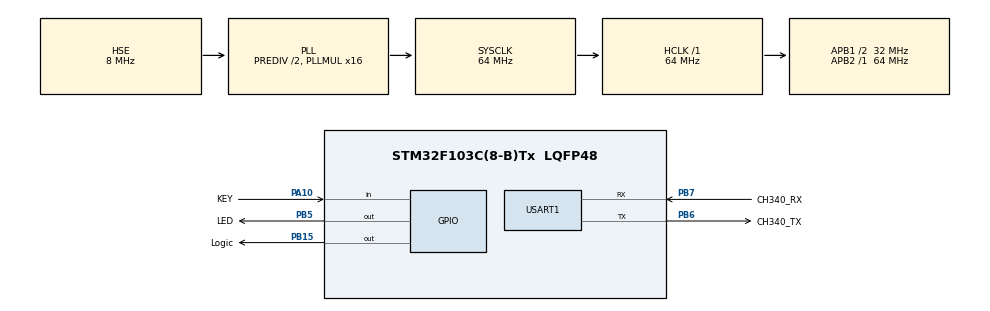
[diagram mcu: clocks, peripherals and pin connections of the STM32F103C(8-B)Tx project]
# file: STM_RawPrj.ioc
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Mcu.Family=STM32F1
Mcu.Name=STM32F103C(8-B)Tx
Mcu.Package=LQFP48
NVIC.PriorityGroup=NVIC_PRIORITYGROUP_4
PA10.GPIO_Label=KEY
PA10.Signal=GPIO_Input
PA13.GPIO_Label=SYS_SWDIO
PA13.Mode=Trace_Asynchronous_SW
PA13.Signal=SYS_JTMS-SWDIO
PA14.GPIO_Label=SYS_SWCLK
PA14.Mode=Trace_Asynchronous_SW
PA14.Signal=SYS_JTCK-SWCLK
PB15.GPIO_Label=Logic
PB15.GPIO_Speed=GPIO_SPEED_FREQ_HIGH
PB15.Signal=GPIO_Output
PB3.GPIO_Label=SYS_SWO
PB3.Mode=Trace_Asynchronous_SW
PB3.Signal=SYS_JTDO-TRACESWO
PB5.GPIO_Label=LED
PB5.GPIO_PuPd=GPIO_NOPULL
PB5.GPIO_Speed=GPIO_SPEED_FREQ_LOW
PB5.Signal=GPIO_Output
PB6.GPIO_Label=CH340_TX
PB6.Mode=Asynchronous
PB6.Signal=USART1_TX
PB7.GPIO_Label=CH340_RX
PB7.Mode=Asynchronous
PB7.Signal=USART1_RX
PC14-OSC32_IN.Mode=LSE-External-Oscillator
PC14-OSC32_IN.Signal=RCC_OSC32_IN
PC15-OSC32_OUT.Mode=LSE-External-Oscillator
PC15-OSC32_OUT.Signal=RCC_OSC32_OUT
PD0-OSC_IN.Mode=HSE-External-Oscillator
PD0-OSC_IN.Signal=RCC_OSC_IN
PD1-OSC_OUT.Mode=HSE-External-Oscillator
PD1-OSC_OUT.Signal=RCC_OSC_OUT
ProjectManager.HeapSize=0x200
ProjectManager.StackSize=0x400
ProjectManager.TargetToolchain=MDK-ARM V5.32
RCC.AHBFreq_Value=64000000
RCC.APB1CLKDivider=RCC_HCLK_DIV2
RCC.APB1Freq_Value=32000000
RCC.APB1TimFreq_Value=64000000
RCC.APB2Freq_Value=64000000
RCC.APB2TimFreq_Value=64000000
RCC.EnbaleCSS=true
RCC.HCLKFreq_Value=64000000
RCC.HSEDivPLL=RCC_HSE_PREDIV_DIV2
RCC.HSICalibrationValue=16
RCC.PLLMUL=RCC_PLL_MUL16
RCC.PLLSourceVirtual=RCC_PLLSOURCE_HSE
RCC.RCC_MCOSource=RCC_MCO1SOURCE_HSE
RCC.SYSCLKFreq_VALUE=64000000
RCC.SYSCLKSource=RCC_SYSCLKSOURCE_PLLCLK
RCC.USBFreq_Value=64000000
USART1.VirtualMode=VM_ASYNC
board=custom

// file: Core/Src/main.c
/* USER CODE BEGIN Header */
/**
  ******************************************************************************
  * @file           : main.c
  * @brief          : Main program body
  ******************************************************************************
  * @attention
  *
  * Copyright (c) 2025 STMicroelectronics.
  * All rights reserved.
  *
  * This software is licensed under terms that can be found in the LICENSE file
  * in the root directory of this software component.
  * If no LICENSE file comes with this software, it is provided AS-IS.
  *
  ******************************************************************************
  */
/* USER CODE END Header */
#include "main.h"
#include "usart.h"
#include "gpio.h"

/* USER CODE BEGIN Includes */
#include <stdio.h>
#include <stdbool.h>
/* USER CODE END Includes */

/* USER CODE BEGIN PV */
GPIO_PinState Key_State = false;
/* USER CODE END PV */

void SystemClock_Config(void);

int main(void)
{

  /* MCU Configuration--------------------------------------------------------*/

  /* Reset of all peripherals, Initializes the Flash interface and the Systick. */
  HAL_Init();

  /* Configure the system clock */
  SystemClock_Config();

  /* Initialize all configured peripherals */
  MX_GPIO_Init();
  MX_USART1_UART_Init();

  /* Infinite loop */
  while (1)
  {

    /* USER CODE BEGIN 3 */
//		HAL_GPIO_WritePin(LED_GPIO_Port, LED_Pin, GPIO_PIN_SET);
//		HAL_Delay(1000);
//		HAL_GPIO_WritePin(LED_GPIO_Port, LED_Pin, GPIO_PIN_RESET);
//		HAL_Delay(1000);

//		HAL_GPIO_TogglePin(LED_GPIO_Port, LED_Pin);
//		HAL_Delay(500);

//		Key_State = HAL_GPIO_ReadPin(KEY_GPIO_Port, KEY_Pin);
//		HAL_Delay(1);

		HAL_GPIO_TogglePin(Logic_GPIO_Port, Logic_Pin);
  }
  /* USER CODE END 3 */
}

void SystemClock_Config(void)
{
  RCC_OscInitTypeDef RCC_OscInitStruct = {0};
  RCC_ClkInitTypeDef RCC_ClkInitStruct = {0};

  /** Initializes the RCC Oscillators according to the specified parameters
  * in the RCC_OscInitTypeDef structure.
  */
  RCC_OscInitStruct.OscillatorType = RCC_OSCILLATORTYPE_HSE;
  RCC_OscInitStruct.HSEState = RCC_HSE_ON;
  RCC_OscInitStruct.HSEPredivValue = RCC_HSE_PREDIV_DIV2;
  RCC_OscInitStruct.HSIState = RCC_HSI_ON;
  RCC_OscInitStruct.PLL.PLLState = RCC_PLL_ON;
  RCC_OscInitStruct.PLL.PLLSource = RCC_PLLSOURCE_HSE;
  RCC_OscInitStruct.PLL.PLLMUL = RCC_PLL_MUL16;
  if (HAL_RCC_OscConfig(&RCC_OscInitStruct) != HAL_OK)
  {
    Error_Handler();
  }

  /** Initializes the CPU, AHB and APB buses clocks
  */
  RCC_ClkInitStruct.ClockType = RCC_CLOCKTYPE_HCLK|RCC_CLOCKTYPE_SYSCLK
                              |RCC_CLOCKTYPE_PCLK1|RCC_CLOCKTYPE_PCLK2;
  RCC_ClkInitStruct.SYSCLKSource = RCC_SYSCLKSOURCE_PLLCLK;
  RCC_ClkInitStruct.AHBCLKDivider = RCC_SYSCLK_DIV1;
  RCC_ClkInitStruct.APB1CLKDivider = RCC_HCLK_DIV2;
  RCC_ClkInitStruct.APB2CLKDivider = RCC_HCLK_DIV1;

  if (HAL_RCC_ClockConfig(&RCC_ClkInitStruct, FLASH_LATENCY_2) != HAL_OK)
  {
    Error_Handler();
  }

  /** Enables the Clock Security System
  */
  HAL_RCC_EnableCSS();
}

void Error_Handler(void)
{
  __disable_irq();
  while (1)
  {
  }
}
